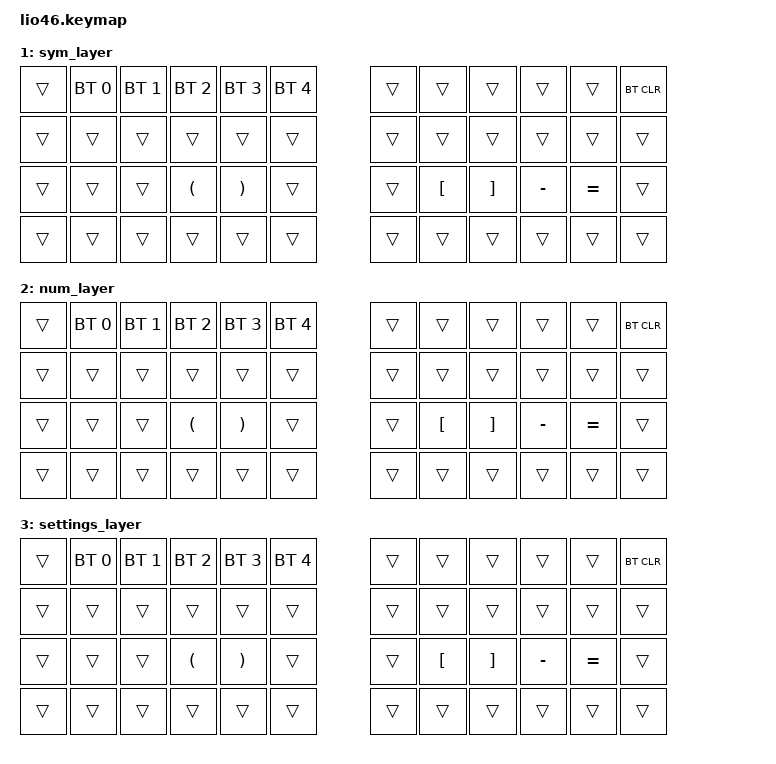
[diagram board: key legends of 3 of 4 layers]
#include <behaviors.dtsi>
#include <dt-bindings/zmk/keys.h>
#include <dt-bindings/zmk/bt.h>

/ {
    keymap {
        compatible = "zmk,keymap";

        default_layer {
            // ---------------------------------------------------------------------------------
            // | ESC  |  Q  |  W  |  E  |  R  |  T  |                |  Y  |  U  |  I  |  O  |  P  |  <-  |
            // | TAB  |  A  |  S  |  D  |  F  |  G  |                |  H  |  J  |  K  |  L  |  ;  |  `   |
            // | LSHFT|  Z  |  X  |  C  |  V  |  B  |                |  N  |  M  |  ,  |  .  |  /  | RCTRL|
            //              | LWIN|LCTRL|LSHFT| ENT | ? |        | ? | SPC | LOW |LARW |DARW |

            bindings = <
                &kp GRAVE  &kp N1    &kp N2    &kp N3     &kp N4     &kp N5               &kp N6     &kp N7  &kp N8     &kp N9    &kp N0    &kp BSPC
                &kp TAB    &kp Q     &kp W     &kp E      &kp R      &kp T                &kp Y      &kp U   &kp I      &kp O     &kp P     &kp BSLH
                &kp CAPS   &kp A     &kp S     &kp D      &kp F      &kp G                &kp H      &kp J   &kp K      &kp L     &kp SEMI  &kp RET
                &kp LSHFT  &kp Z     &kp X     &kp C      &kp V      &kp B                &kp N      &kp M   &kp COMMA  &kp DOT   &kp FSLH  &kp APOS
                &kp LCTRL  &kp LALT  &kp LGUI  &kp SPACE  &kp LALT   &kp LGUI             &kp SPACE  &mo 1   &kp LARW   &kp DARW  &kp UARW  &kp RARW
            >;
        };
        sym_layer {
            // ------------------------------------------------------------------------------------------------------------
            // |       |  BT1  |  BT2  |  BT3  |  BT4  |  BT5  |          |       |       |       |       |       | BTCLR |
            // |       |       |       |       |       |       |          |       |       |       |       |       |       |
            // |       |       |       | LPAR  | RPAR  |       |          |       | LBKT  | RBKT  |       |       |       |
            // |       |       |       |       |       |       |          |       |       |       |       |       |       |

            bindings = <
                &trans    &bt BT_SEL 0   &bt BT_SEL 1   &bt BT_SEL 2   &bt BT_SEL 3   &bt BT_SEL 4           &trans    &trans    &trans   &trans   &trans  &bt BT_CLR
                &trans    &trans         &trans         &trans         &trans         &trans                 &trans    &trans    &trans   &trans   &trans  &trans
                &trans    &trans         &trans         &kp LPAR       &kp RPAR       &trans                 &trans    &kp LBKT  &kp RBKT &kp MINUS   &kp EQUAL  &trans
                &trans    &trans         &trans         &trans         &trans         &trans                 &trans    &trans    &trans   &trans   &trans  &trans
            >;
        };
        num_layer {
            // ------------------------------------------------------------------------------------------------------------
            // |       |  BT1  |  BT2  |  BT3  |  BT4  |  BT5  |          |       |       |       |       |       | BTCLR |
            // |       |       |       |       |       |       |          |       |       |       |       |       |       |
            // |       |       |       | LPAR  | RPAR  |       |          |       | LBKT  | RBKT  |       |       |       |
            // |       |       |       |       |       |       |          |       |       |       |       |       |       |

            bindings = <
                &trans    &bt BT_SEL 0   &bt BT_SEL 1   &bt BT_SEL 2   &bt BT_SEL 3   &bt BT_SEL 4           &trans    &trans    &trans   &trans   &trans  &bt BT_CLR
                &trans    &trans         &trans         &trans         &trans         &trans                 &trans    &trans    &trans   &trans   &trans  &trans
                &trans    &trans         &trans         &kp LPAR       &kp RPAR       &trans                 &trans    &kp LBKT  &kp RBKT &kp MINUS   &kp EQUAL  &trans
                &trans    &trans         &trans         &trans         &trans         &trans                 &trans    &trans    &trans   &trans   &trans  &trans
            >;
        };
        settings_layer {
            // ------------------------------------------------------------------------------------------------------------
            // |       |  BT1  |  BT2  |  BT3  |  BT4  |  BT5  |          |       |       |       |       |       | BTCLR |
            // |       |       |       |       |       |       |          |       |       |       |       |       |       |
            // |       |       |       | LPAR  | RPAR  |       |          |       | LBKT  | RBKT  |       |       |       |
            // |       |       |       |       |       |       |          |       |       |       |       |       |       |

            bindings = <
                &trans    &bt BT_SEL 0   &bt BT_SEL 1   &bt BT_SEL 2   &bt BT_SEL 3   &bt BT_SEL 4           &trans    &trans    &trans   &trans   &trans  &bt BT_CLR
                &trans    &trans         &trans         &trans         &trans         &trans                 &trans    &trans    &trans   &trans   &trans  &trans
                &trans    &trans         &trans         &kp LPAR       &kp RPAR       &trans                 &trans    &kp LBKT  &kp RBKT &kp MINUS   &kp EQUAL  &trans
                &trans    &trans         &trans         &trans         &trans         &trans                 &trans    &trans    &trans   &trans   &trans  &trans
            >;
        };
    };
};
